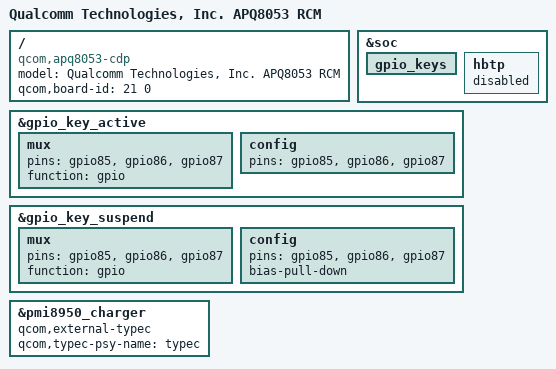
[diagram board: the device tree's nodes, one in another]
/*
 * Copyright (c) 2016-2017, The Linux Foundation. All rights reserved.
 *
 * This program is free software; you can redistribute it and/or modify
 * it under the terms of the GNU General Public License version 2 and
 * only version 2 as published by the Free Software Foundation.
 *
 * This program is distributed in the hope that it will be useful,
 * but WITHOUT ANY WARRANTY; without even the implied warranty of
 * MERCHANTABILITY or FITNESS FOR A PARTICULAR PURPOSE.  See the
 * GNU General Public License for more details.
 */

/dts-v1/;

#include "apq8053.dtsi"
#include "msm-pmi8950.dtsi"
#include "msm8953-cdp.dtsi"
#include "msm8953-audio-cdp.dtsi"
#include "msm8953-pmi8950.dtsi"
#include "msm8953-camera-sensor-cdp.dtsi"

/ {
	model = "Qualcomm Technologies, Inc. APQ8053 RCM";
	compatible = "qcom,apq8053-cdp", "qcom,apq8053", "qcom,cdp";
	qcom,board-id= <21 0>;
};

&soc {
	gpio_keys {
		/delete-node/ home;
	};

	hbtp {
		status = "disabled";
	};
};

&gpio_key_active {
	mux {
		pins = "gpio85", "gpio86", "gpio87";
		function = "gpio";
	};

	config {
		pins = "gpio85", "gpio86", "gpio87";
	};
};

&gpio_key_suspend {
	mux {
		pins = "gpio85", "gpio86", "gpio87";
		function = "gpio";
	};

	config {
		pins = "gpio85", "gpio86", "gpio87";
		/delete-property/ bias-pull-up;
		bias-pull-down;
	};
};

&pmi8950_charger {
	qcom,external-typec;
	qcom,typec-psy-name = "typec";
};
